AUTOSAR XML (schema 00046)
package /RTE_Events_Lab
  sender receiver interface SRI_Inputs
    data Val1: type=uint16
    data Val2: type=uint16
  sender receiver interface SRI_Outputs
    data SumResult: type=uint32
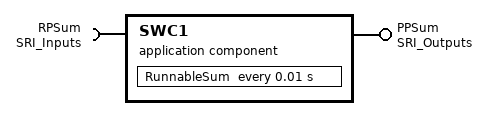
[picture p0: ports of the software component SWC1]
  application sw component type SWC1
    provide port PPSum: provided-interface=SRI_Outputs
    require port RPSum: required-interface=SRI_Inputs
    behavior IntBehavior
      timing event TE_10ms: start-on-event=RunnableSum, period=0.01
      init event InitEvent: start-on-event=RunnableSum
      data received event DRCEvent: start-on-event=RunnableSum, data=Val1
      data write completed event DWCEvent: start-on-event=RunnableSum, event-source=SumVal
      runnable RunnableSum: symbol=Sum
        data-read-access:
          access Value1: accessed-variable=RPSum.Val1
          access Value2: accessed-variable=RPSum.Val2
        data-write-access:
          access SumVal: accessed-variable=PPSum.SumResult
